# jbr_MDR1901VC1T register map
Registers are 32-bit, access not given, no defined reset value unless marked. A register's access mark holds for its fields unless they carry their own. Addresses are absolute; registers are grouped by the start of their names; [hi:lo] are bit positions.

## SSP2
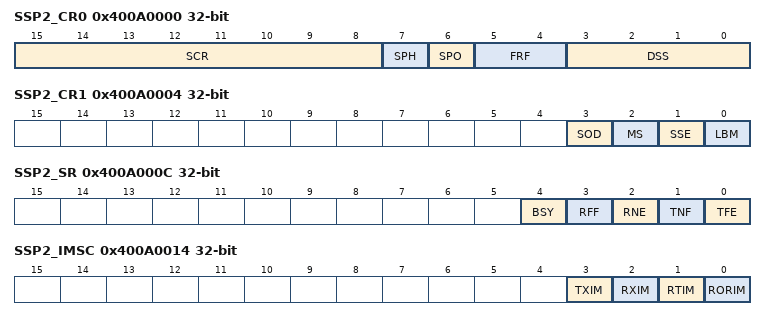
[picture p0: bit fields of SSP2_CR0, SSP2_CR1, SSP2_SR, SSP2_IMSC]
0x400A0000 SSP2_CR0
  [15:8] SCR, [7] SPH, [6] SPO, [5:4] FRF, [3:0] DSS
0x400A0004 SSP2_CR1
  [3] SOD, [2] MS, [1] SSE, [0] LBM
0x400A0008 SSP2_DR
  [15:0] DATA
0x400A000C SSP2_SR
  [4] BSY, [3] RFF, [2] RNE, [1] TNF, [0] TFE
0x400A0010 SSP2_CPSR
  [7:0] CPSDVSR
0x400A0014 SSP2_IMSC
  [3] TXIM, [2] RXIM, [1] RTIM, [0] RORIM
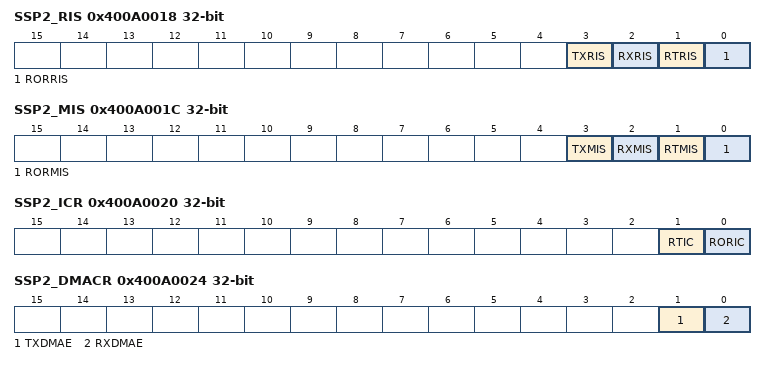
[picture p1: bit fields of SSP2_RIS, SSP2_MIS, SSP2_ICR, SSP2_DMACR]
0x400A0018 SSP2_RIS
  [3] TXRIS, [2] RXRIS, [1] RTRIS, [0] RORRIS
0x400A001C SSP2_MIS
  [3] TXMIS, [2] RXMIS, [1] RTMIS, [0] RORMIS
0x400A0020 SSP2_ICR
  [1] RTIC, [0] RORIC
0x400A0024 SSP2_DMACR
  [1] TXDMAE, [0] RXDMAE

## SSP3
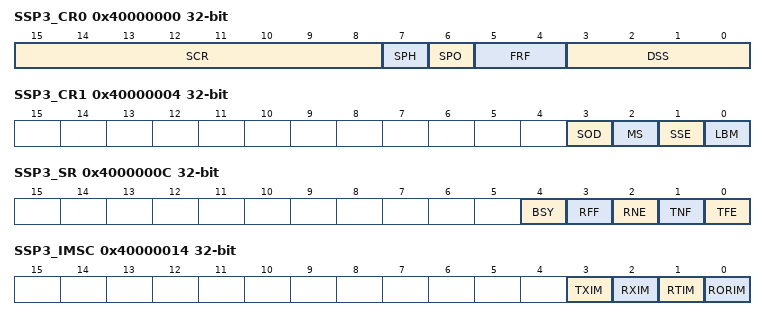
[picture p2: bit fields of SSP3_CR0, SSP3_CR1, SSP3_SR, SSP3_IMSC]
0x40000000 SSP3_CR0
  [15:8] SCR, [7] SPH, [6] SPO, [5:4] FRF, [3:0] DSS
0x40000004 SSP3_CR1
  [3] SOD, [2] MS, [1] SSE, [0] LBM
0x40000008 SSP3_DR
  [15:0] DATA
0x4000000C SSP3_SR
  [4] BSY, [3] RFF, [2] RNE, [1] TNF, [0] TFE
0x40000010 SSP3_CPSR
  [7:0] CPSDVSR
0x40000014 SSP3_IMSC
  [3] TXIM, [2] RXIM, [1] RTIM, [0] RORIM
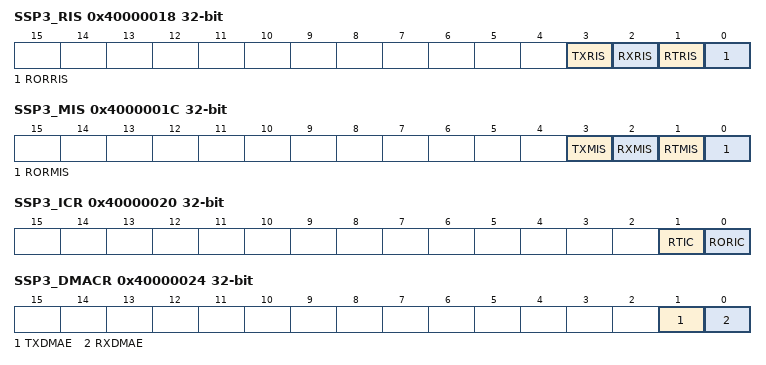
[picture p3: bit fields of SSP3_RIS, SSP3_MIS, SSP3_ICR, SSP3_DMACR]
0x40000018 SSP3_RIS
  [3] TXRIS, [2] RXRIS, [1] RTRIS, [0] RORRIS
0x4000001C SSP3_MIS
  [3] TXMIS, [2] RXMIS, [1] RTMIS, [0] RORMIS
0x40000020 SSP3_ICR
  [1] RTIC, [0] RORIC
0x40000024 SSP3_DMACR
  [1] TXDMAE, [0] RXDMAE

## SSP4
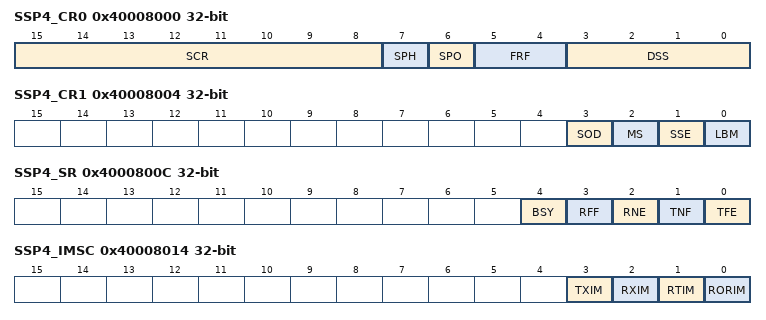
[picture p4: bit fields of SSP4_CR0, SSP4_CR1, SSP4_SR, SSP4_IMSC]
0x40008000 SSP4_CR0
  [15:8] SCR, [7] SPH, [6] SPO, [5:4] FRF, [3:0] DSS
0x40008004 SSP4_CR1
  [3] SOD, [2] MS, [1] SSE, [0] LBM
0x40008008 SSP4_DR
  [15:0] DATA
0x4000800C SSP4_SR
  [4] BSY, [3] RFF, [2] RNE, [1] TNF, [0] TFE
0x40008010 SSP4_CPSR
  [7:0] CPSDVSR
0x40008014 SSP4_IMSC
  [3] TXIM, [2] RXIM, [1] RTIM, [0] RORIM
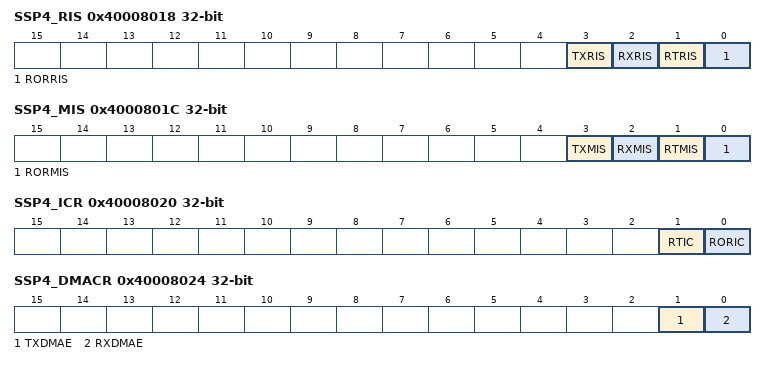
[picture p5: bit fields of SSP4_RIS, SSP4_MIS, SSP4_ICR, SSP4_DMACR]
0x40008018 SSP4_RIS
  [3] TXRIS, [2] RXRIS, [1] RTRIS, [0] RORRIS
0x4000801C SSP4_MIS
  [3] TXMIS, [2] RXMIS, [1] RTMIS, [0] RORMIS
0x40008020 SSP4_ICR
  [1] RTIC, [0] RORIC
0x40008024 SSP4_DMACR
  [1] TXDMAE, [0] RXDMAE

## UART1
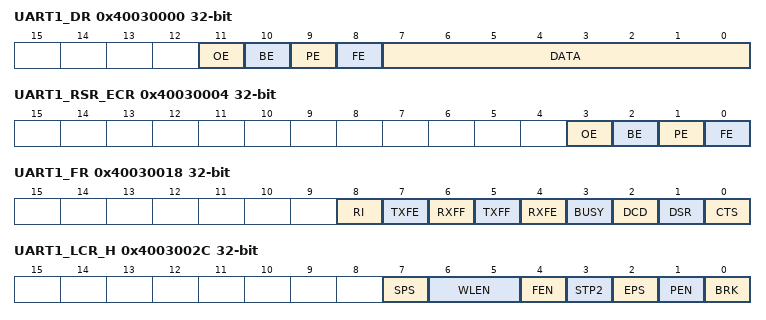
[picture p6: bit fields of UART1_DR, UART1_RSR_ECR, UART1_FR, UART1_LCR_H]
0x40030000 UART1_DR
  [11] OE, [10] BE, [9] PE, [8] FE, [7:0] DATA
0x40030004 UART1_RSR_ECR
  [3] OE, [2] BE, [1] PE, [0] FE
0x40030018 UART1_FR
  [8] RI, [7] TXFE, [6] RXFF, [5] TXFF, [4] RXFE, [3] BUSY, [2] DCD, [1] DSR, [0] CTS
0x40030020 UART1_ILPR
  [7:0] ILPDVSR
0x40030024 UART1_IBRD
  [15:0] BAUD_DIVINT
0x40030028 UART1_FBRD
  [5:0] BAUD_DIVFRAC
0x4003002C UART1_LCR_H
  [7] SPS, [6:5] WLEN, [4] FEN, [3] STP2, [2] EPS, [1] PEN, [0] BRK
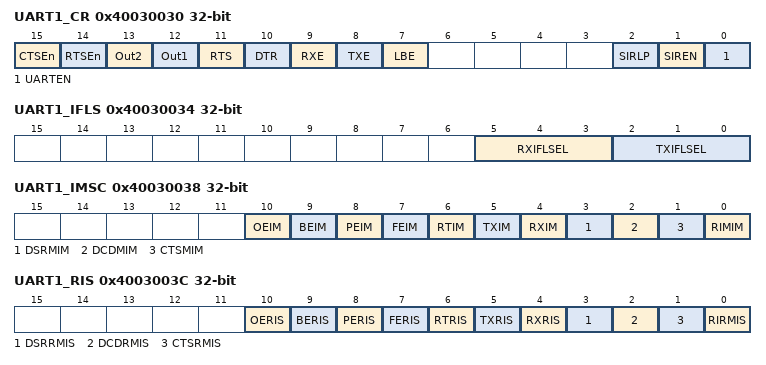
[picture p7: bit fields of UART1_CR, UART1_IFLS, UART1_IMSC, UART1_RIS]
0x40030030 UART1_CR
  [15] CTSEn, [14] RTSEn, [13] Out2, [12] Out1, [11] RTS, [10] DTR, [9] RXE, [8] TXE, [7] LBE, [2] SIRLP, [1] SIREN, [0] UARTEN
0x40030034 UART1_IFLS
  [5:3] RXIFLSEL, [2:0] TXIFLSEL
0x40030038 UART1_IMSC
  [10] OEIM, [9] BEIM, [8] PEIM, [7] FEIM, [6] RTIM, [5] TXIM, [4] RXIM, [3] DSRMIM, [2] DCDMIM, [1] CTSMIM, [0] RIMIM
0x4003003C UART1_RIS
  [10] OERIS, [9] BERIS, [8] PERIS, [7] FERIS, [6] RTRIS, [5] TXRIS, [4] RXRIS, [3] DSRRMIS, [2] DCDRMIS, [1] CTSRMIS, [0] RIRMIS
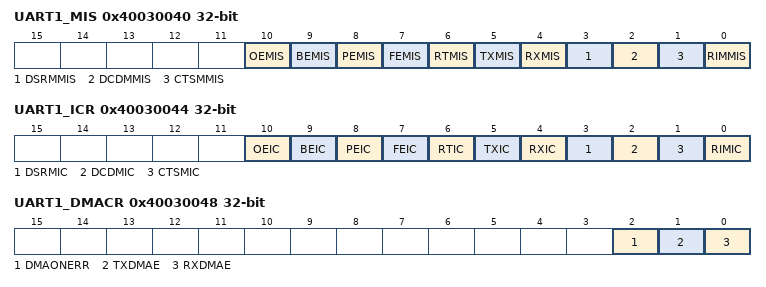
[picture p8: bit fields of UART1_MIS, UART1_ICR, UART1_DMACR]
0x40030040 UART1_MIS
  [10] OEMIS, [9] BEMIS, [8] PEMIS, [7] FEMIS, [6] RTMIS, [5] TXMIS, [4] RXMIS, [3] DSRMMIS, [2] DCDMMIS, [1] CTSMMIS, [0] RIMMIS
0x40030044 UART1_ICR
  [10] OEIC, [9] BEIC, [8] PEIC, [7] FEIC, [6] RTIC, [5] TXIC, [4] RXIC, [3] DSRMIC, [2] DCDMIC, [1] CTSMIC, [0] RIMIC
0x40030048 UART1_DMACR
  [2] DMAONERR, [1] TXDMAE, [0] RXDMAE

## UART2
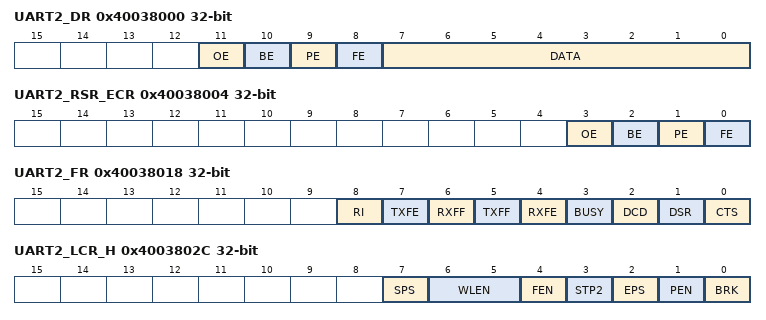
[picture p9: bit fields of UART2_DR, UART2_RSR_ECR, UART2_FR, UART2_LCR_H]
0x40038000 UART2_DR
  [11] OE, [10] BE, [9] PE, [8] FE, [7:0] DATA
0x40038004 UART2_RSR_ECR
  [3] OE, [2] BE, [1] PE, [0] FE
0x40038018 UART2_FR
  [8] RI, [7] TXFE, [6] RXFF, [5] TXFF, [4] RXFE, [3] BUSY, [2] DCD, [1] DSR, [0] CTS
0x40038020 UART2_ILPR
  [7:0] ILPDVSR
0x40038024 UART2_IBRD
  [15:0] BAUD_DIVINT
0x40038028 UART2_FBRD
  [5:0] BAUD_DIVFRAC
0x4003802C UART2_LCR_H
  [7] SPS, [6:5] WLEN, [4] FEN, [3] STP2, [2] EPS, [1] PEN, [0] BRK
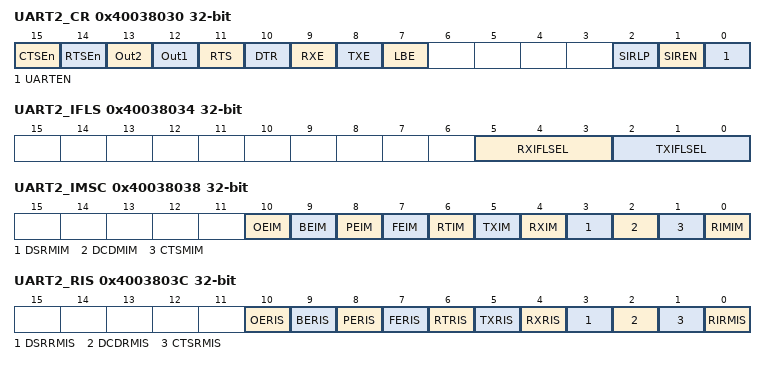
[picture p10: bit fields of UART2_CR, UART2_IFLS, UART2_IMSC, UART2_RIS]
0x40038030 UART2_CR
  [15] CTSEn, [14] RTSEn, [13] Out2, [12] Out1, [11] RTS, [10] DTR, [9] RXE, [8] TXE, [7] LBE, [2] SIRLP, [1] SIREN, [0] UARTEN
0x40038034 UART2_IFLS
  [5:3] RXIFLSEL, [2:0] TXIFLSEL
0x40038038 UART2_IMSC
  [10] OEIM, [9] BEIM, [8] PEIM, [7] FEIM, [6] RTIM, [5] TXIM, [4] RXIM, [3] DSRMIM, [2] DCDMIM, [1] CTSMIM, [0] RIMIM
0x4003803C UART2_RIS
  [10] OERIS, [9] BERIS, [8] PERIS, [7] FERIS, [6] RTRIS, [5] TXRIS, [4] RXRIS, [3] DSRRMIS, [2] DCDRMIS, [1] CTSRMIS, [0] RIRMIS
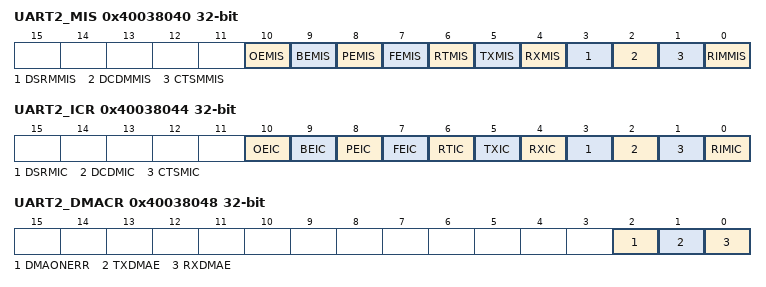
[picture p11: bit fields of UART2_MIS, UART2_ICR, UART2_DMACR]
0x40038040 UART2_MIS
  [10] OEMIS, [9] BEMIS, [8] PEMIS, [7] FEMIS, [6] RTMIS, [5] TXMIS, [4] RXMIS, [3] DSRMMIS, [2] DCDMMIS, [1] CTSMMIS, [0] RIMMIS
0x40038044 UART2_ICR
  [10] OEIC, [9] BEIC, [8] PEIC, [7] FEIC, [6] RTIC, [5] TXIC, [4] RXIC, [3] DSRMIC, [2] DCDMIC, [1] CTSMIC, [0] RIMIC
0x40038048 UART2_DMACR
  [2] DMAONERR, [1] TXDMAE, [0] RXDMAE
